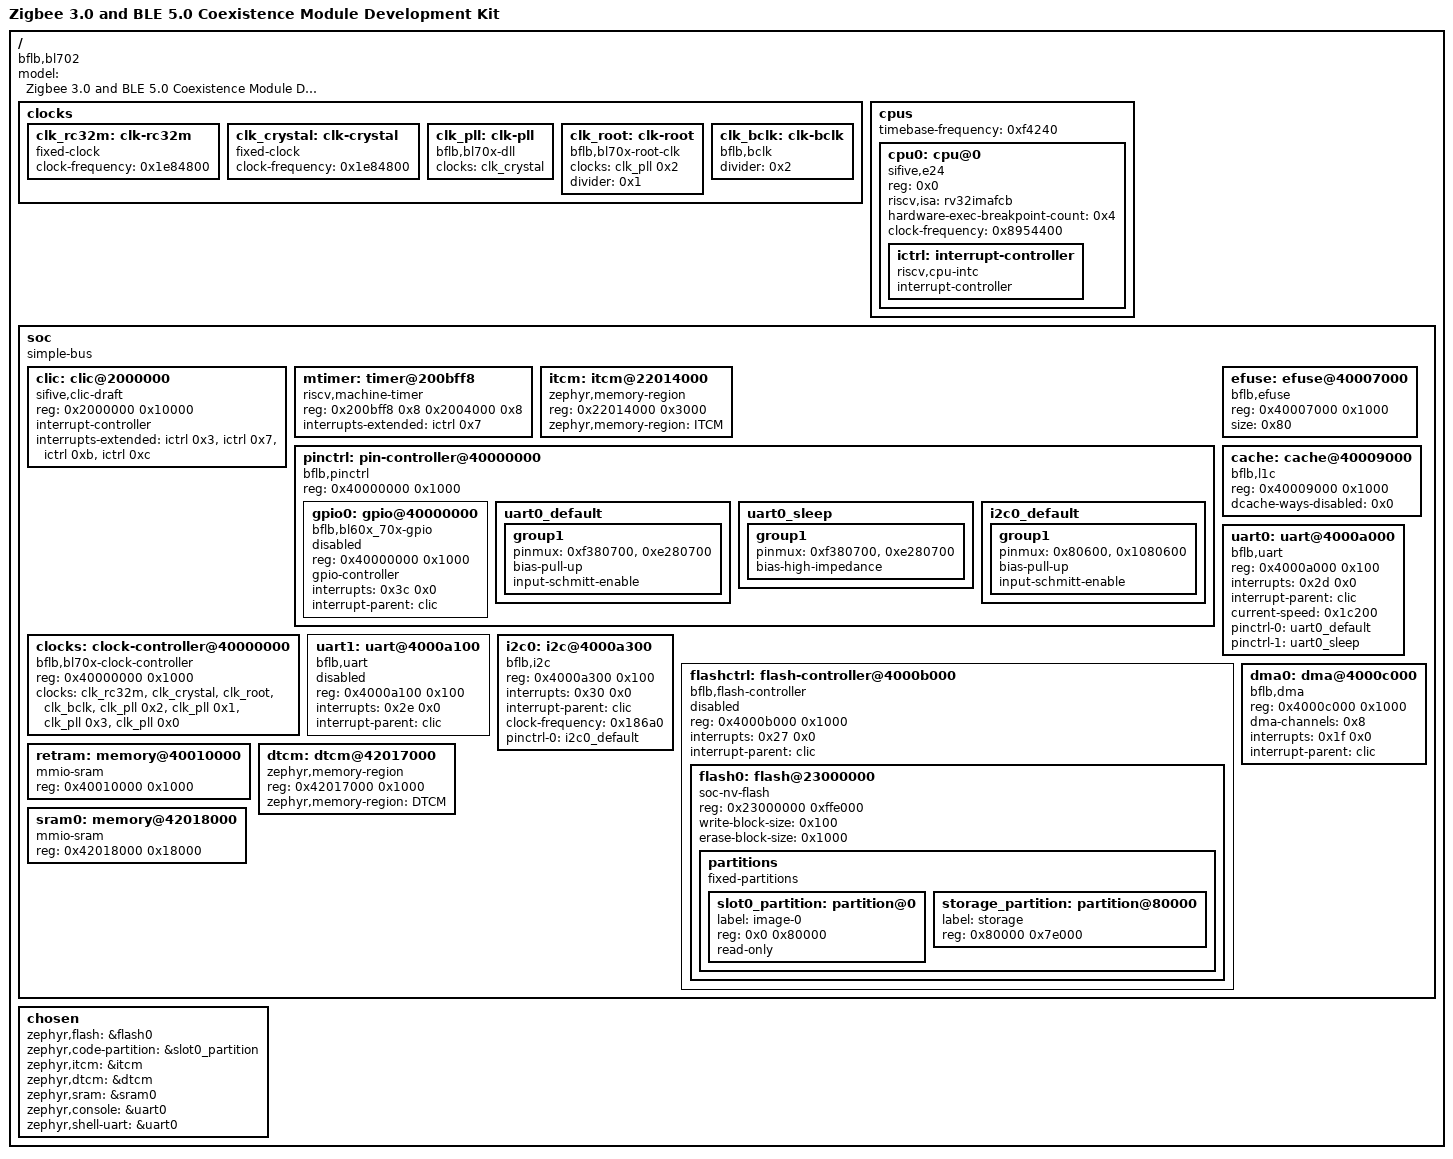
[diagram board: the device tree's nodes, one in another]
/dts-v1/;

/* node '/' defined in zephyr/dts/riscv/bflb/bl70x.dtsi:14 */
/ {
	#address-cells = < 0x1 >;                                            /* in zephyr/dts/riscv/bflb/bl70x.dtsi:15 */
	#size-cells = < 0x1 >;                                               /* in zephyr/dts/riscv/bflb/bl70x.dtsi:16 */
	model = "Zigbee 3.0 and BLE 5.0 Coexistence Module Development Kit"; /* in zephyr/boards/doiting/dt_xt_zb1_devkit/dt_xt_zb1_devkit.dts:12 */
	compatible = "bflb,bl702";                                           /* in zephyr/boards/doiting/dt_xt_zb1_devkit/dt_xt_zb1_devkit.dts:13 */

	/* node '/clocks' defined in zephyr/dts/riscv/bflb/bl70x.dtsi:18 */
	clocks {

		/* node '/clocks/clk-rc32m' defined in zephyr/dts/riscv/bflb/bl70x.dtsi:19 */
		clk_rc32m: clk-rc32m {
			#clock-cells = < 0x0 >;          /* in zephyr/dts/riscv/bflb/bl70x.dtsi:20 */
			compatible = "fixed-clock";      /* in zephyr/dts/riscv/bflb/bl70x.dtsi:21 */
			clock-frequency = < 0x1e84800 >; /* in zephyr/dts/riscv/bflb/bl70x.dtsi:22 */
			status = "okay";                 /* in zephyr/dts/riscv/bflb/bl70x.dtsi:23 */
			phandle = < 0x5 >;               /* in zephyr/dts/riscv/bflb/bl70x.dtsi:137 */
		};

		/* node '/clocks/clk-crystal' defined in zephyr/dts/riscv/bflb/bl70x.dtsi:26 */
		clk_crystal: clk-crystal {
			#clock-cells = < 0x0 >;          /* in zephyr/dts/riscv/bflb/bl70x.dtsi:27 */
			compatible = "fixed-clock";      /* in zephyr/dts/riscv/bflb/bl70x.dtsi:28 */
			clock-frequency = < 0x1e84800 >; /* in zephyr/dts/riscv/bflb/bl70x.dtsi:29 */
			status = "okay";                 /* in zephyr/dts/riscv/bflb/bl70x.dtsi:30 */
			phandle = < 0x1 >;               /* in zephyr/dts/riscv/bflb/bl70x.dtsi:36 */
		};

		/* node '/clocks/clk-pll' defined in zephyr/dts/riscv/bflb/bl70x.dtsi:33 */
		clk_pll: clk-pll {
			#clock-cells = < 0x1 >;        /* in zephyr/dts/riscv/bflb/bl70x.dtsi:34 */
			compatible = "bflb,bl70x-dll"; /* in zephyr/dts/riscv/bflb/bl70x.dtsi:35 */
			clocks = < &clk_crystal >;     /* in zephyr/dts/riscv/bflb/bl70x.dtsi:36 */
			status = "okay";               /* in zephyr/dts/riscv/bflb/bl70x.dtsi:37 */
			phandle = < 0x2 >;             /* in zephyr/dts/riscv/bflb/bl70x.dtsi:43 */
		};

		/* node '/clocks/clk-root' defined in zephyr/dts/riscv/bflb/bl70x.dtsi:40 */
		clk_root: clk-root {
			#clock-cells = < 0x0 >;             /* in zephyr/dts/riscv/bflb/bl70x.dtsi:41 */
			compatible = "bflb,bl70x-root-clk"; /* in zephyr/dts/riscv/bflb/bl70x.dtsi:42 */
			clocks = < &clk_pll 0x2 >;          /* in zephyr/dts/riscv/bflb/bl70x.dtsi:43 */
			divider = < 0x1 >;                  /* in zephyr/dts/riscv/bflb/bl70x.dtsi:44 */
			status = "okay";                    /* in zephyr/dts/riscv/bflb/bl70x.dtsi:45 */
			phandle = < 0x6 >;                  /* in zephyr/dts/riscv/bflb/bl70x.dtsi:137 */
		};

		/* node '/clocks/clk-bclk' defined in zephyr/dts/riscv/bflb/bl70x.dtsi:48 */
		clk_bclk: clk-bclk {
			#clock-cells = < 0x0 >;   /* in zephyr/dts/riscv/bflb/bl70x.dtsi:49 */
			compatible = "bflb,bclk"; /* in zephyr/dts/riscv/bflb/bl70x.dtsi:50 */
			divider = < 0x2 >;        /* in zephyr/dts/riscv/bflb/bl70x.dtsi:51 */
			status = "okay";          /* in zephyr/dts/riscv/bflb/bl70x.dtsi:52 */
			phandle = < 0x7 >;        /* in zephyr/dts/riscv/bflb/bl70x.dtsi:137 */
		};
	};

	/* node '/cpus' defined in zephyr/dts/riscv/bflb/bl70x.dtsi:56 */
	cpus {
		#address-cells = < 0x1 >;         /* in zephyr/dts/riscv/bflb/bl70x.dtsi:57 */
		#size-cells = < 0x0 >;            /* in zephyr/dts/riscv/bflb/bl70x.dtsi:58 */
		timebase-frequency = < 0xf4240 >; /* in zephyr/dts/riscv/bflb/bl70x.dtsi:59 */

		/* node '/cpus/cpu@0' defined in zephyr/dts/riscv/bflb/bl70x.dtsi:61 */
		cpu0: cpu@0 {
			device_type = "cpu";                      /* in zephyr/dts/riscv/bflb/bl70x.dtsi:62 */
			compatible = "sifive,e24",
			             "riscv";                     /* in zephyr/dts/riscv/bflb/bl70x.dtsi:63 */
			reg = < 0x0 >;                            /* in zephyr/dts/riscv/bflb/bl70x.dtsi:64 */
			riscv,isa = "rv32imafcb";                 /* in zephyr/dts/riscv/bflb/bl70x.dtsi:65 */
			hardware-exec-breakpoint-count = < 0x4 >; /* in zephyr/dts/riscv/bflb/bl70x.dtsi:66 */
			status = "okay";                          /* in zephyr/dts/riscv/bflb/bl70x.dtsi:67 */
			clock-frequency = < 0x8954400 >;          /* in zephyr/boards/doiting/dt_xt_zb1_devkit/dt_xt_zb1_devkit.dts:27 */

			/* node '/cpus/cpu@0/interrupt-controller' defined in zephyr/dts/riscv/bflb/bl70x.dtsi:69 */
			ictrl: interrupt-controller {
				#address-cells = < 0x0 >;      /* in zephyr/dts/riscv/bflb/bl70x.dtsi:70 */
				#interrupt-cells = < 0x1 >;    /* in zephyr/dts/riscv/bflb/bl70x.dtsi:71 */
				compatible = "riscv,cpu-intc"; /* in zephyr/dts/riscv/bflb/bl70x.dtsi:72 */
				interrupt-controller;          /* in zephyr/dts/riscv/bflb/bl70x.dtsi:73 */
				phandle = < 0x3 >;             /* in zephyr/dts/riscv/bflb/bl70x.dtsi:91 */
			};
		};
	};

	/* node '/soc' defined in zephyr/dts/riscv/bflb/bl70x.dtsi:78 */
	soc {
		compatible = "simple-bus"; /* in zephyr/dts/riscv/bflb/bl70x.dtsi:79 */
		#address-cells = < 0x1 >;  /* in zephyr/dts/riscv/bflb/bl70x.dtsi:80 */
		#size-cells = < 0x1 >;     /* in zephyr/dts/riscv/bflb/bl70x.dtsi:81 */
		ranges;                    /* in zephyr/dts/riscv/bflb/bl70x.dtsi:82 */

		/* node '/soc/clic@2000000' defined in zephyr/dts/riscv/bflb/bl70x.dtsi:84 */
		clic: clic@2000000 {
			compatible = "sifive,clic-draft";                                      /* in zephyr/dts/riscv/bflb/bl70x.dtsi:85 */
			reg = < 0x2000000 0x10000 >;                                           /* in zephyr/dts/riscv/bflb/bl70x.dtsi:86 */
			#address-cells = < 0x0 >;                                              /* in zephyr/dts/riscv/bflb/bl70x.dtsi:87 */
			#interrupt-cells = < 0x2 >;                                            /* in zephyr/dts/riscv/bflb/bl70x.dtsi:88 */
			interrupt-controller;                                                  /* in zephyr/dts/riscv/bflb/bl70x.dtsi:90 */
			interrupts-extended = < &ictrl 0x3 &ictrl 0x7 &ictrl 0xb &ictrl 0xc >; /* in zephyr/dts/riscv/bflb/bl70x.dtsi:91 */
			interrupt-names = "msip",
			                  "mtip",
			                  "meip",
			                  "csip";                                              /* in zephyr/dts/riscv/bflb/bl70x.dtsi:92 */
			phandle = < 0x4 >;                                                     /* in zephyr/dts/riscv/bflb/bl70x.dtsi:128 */
		};

		/* node '/soc/timer@200bff8' defined in zephyr/dts/riscv/bflb/bl70x.dtsi:98 */
		mtimer: timer@200bff8 {
			compatible = "riscv,machine-timer";    /* in zephyr/dts/riscv/bflb/bl70x.dtsi:99 */
			reg = < 0x200bff8 0x8 0x2004000 0x8 >; /* in zephyr/dts/riscv/bflb/bl70x.dtsi:100 */
			reg-names = "mtime",
			            "mtimecmp";                /* in zephyr/dts/riscv/bflb/bl70x.dtsi:101 */
			interrupts-extended = < &ictrl 0x7 >;  /* in zephyr/dts/riscv/bflb/bl70x.dtsi:103 */
		};

		/* node '/soc/itcm@22014000' defined in zephyr/dts/riscv/bflb/bl70x.dtsi:106 */
		itcm: itcm@22014000 {
			compatible = "zephyr,memory-region",
			             "sifive,dtim0";         /* in zephyr/dts/riscv/bflb/bl70x.dtsi:107 */
			reg = < 0x22014000 0x3000 >;         /* in zephyr/dts/riscv/bflb/bl70x.dtsi:108 */
			zephyr,memory-region = "ITCM";       /* in zephyr/dts/riscv/bflb/bl70x.dtsi:109 */
		};

		/* node '/soc/pin-controller@40000000' defined in zephyr/dts/riscv/bflb/bl70x.dtsi:112 */
		pinctrl: pin-controller@40000000 {
			compatible = "bflb,pinctrl";               /* in zephyr/dts/riscv/bflb/bl70x.dtsi:113 */
			reg = < 0x40000000 0x1000 >;               /* in zephyr/dts/riscv/bflb/bl70x.dtsi:114 */
			ranges = < 0x40000000 0x40000000 0x1000 >; /* in zephyr/dts/riscv/bflb/bl70x.dtsi:115 */
			#address-cells = < 0x1 >;                  /* in zephyr/dts/riscv/bflb/bl70x.dtsi:116 */
			#size-cells = < 0x1 >;                     /* in zephyr/dts/riscv/bflb/bl70x.dtsi:117 */
			status = "okay";                           /* in zephyr/dts/riscv/bflb/bl70x.dtsi:118 */

			/* node '/soc/pin-controller@40000000/gpio@40000000' defined in zephyr/dts/riscv/bflb/bl70x.dtsi:120 */
			gpio0: gpio@40000000 {
				compatible = "bflb,bl60x_70x-gpio"; /* in zephyr/dts/riscv/bflb/bl70x.dtsi:121 */
				reg = < 0x40000000 0x1000 >;        /* in zephyr/dts/riscv/bflb/bl70x.dtsi:122 */
				#gpio-cells = < 0x2 >;              /* in zephyr/dts/riscv/bflb/bl70x.dtsi:123 */
				status = "disabled";                /* in zephyr/dts/riscv/bflb/bl70x.dtsi:124 */
				gpio-controller;                    /* in zephyr/dts/riscv/bflb/bl70x.dtsi:126 */
				interrupts = < 0x3c 0x0 >;          /* in zephyr/dts/riscv/bflb/bl70x.dtsi:127 */
				interrupt-parent = < &clic >;       /* in zephyr/dts/riscv/bflb/bl70x.dtsi:128 */
			};

			/* node '/soc/pin-controller@40000000/uart0_default' defined in zephyr/boards/doiting/dt_xt_zb1_devkit/dt_xt_zb1_devkit-pinctrl.dtsi:9 */
			uart0_default: uart0_default {
				phandle = < 0x8 >; /* in zephyr/boards/doiting/dt_xt_zb1_devkit/dt_xt_zb1_devkit.dts:60 */

				/* node '/soc/pin-controller@40000000/uart0_default/group1' defined in zephyr/boards/doiting/dt_xt_zb1_devkit/dt_xt_zb1_devkit-pinctrl.dtsi:10 */
				group1 {
					pinmux = < 0xf380700 >,
					         < 0xe280700 >; /* in zephyr/boards/doiting/dt_xt_zb1_devkit/dt_xt_zb1_devkit-pinctrl.dtsi:11 */
					bias-pull-up;           /* in zephyr/boards/doiting/dt_xt_zb1_devkit/dt_xt_zb1_devkit-pinctrl.dtsi:13 */
					input-schmitt-enable;   /* in zephyr/boards/doiting/dt_xt_zb1_devkit/dt_xt_zb1_devkit-pinctrl.dtsi:14 */
				};
			};

			/* node '/soc/pin-controller@40000000/uart0_sleep' defined in zephyr/boards/doiting/dt_xt_zb1_devkit/dt_xt_zb1_devkit-pinctrl.dtsi:18 */
			uart0_sleep: uart0_sleep {
				phandle = < 0x9 >; /* in zephyr/boards/doiting/dt_xt_zb1_devkit/dt_xt_zb1_devkit.dts:61 */

				/* node '/soc/pin-controller@40000000/uart0_sleep/group1' defined in zephyr/boards/doiting/dt_xt_zb1_devkit/dt_xt_zb1_devkit-pinctrl.dtsi:19 */
				group1 {
					pinmux = < 0xf380700 >,
					         < 0xe280700 >; /* in zephyr/boards/doiting/dt_xt_zb1_devkit/dt_xt_zb1_devkit-pinctrl.dtsi:20 */
					bias-high-impedance;    /* in zephyr/boards/doiting/dt_xt_zb1_devkit/dt_xt_zb1_devkit-pinctrl.dtsi:22 */
				};
			};

			/* node '/soc/pin-controller@40000000/i2c0_default' defined in zephyr/boards/doiting/dt_xt_zb1_devkit/dt_xt_zb1_devkit-pinctrl.dtsi:26 */
			i2c0_default: i2c0_default {
				phandle = < 0xa >; /* in zephyr/boards/doiting/dt_xt_zb1_devkit/dt_xt_zb1_devkit.dts:69 */

				/* node '/soc/pin-controller@40000000/i2c0_default/group1' defined in zephyr/boards/doiting/dt_xt_zb1_devkit/dt_xt_zb1_devkit-pinctrl.dtsi:27 */
				group1 {
					pinmux = < 0x80600 >,
					         < 0x1080600 >; /* in zephyr/boards/doiting/dt_xt_zb1_devkit/dt_xt_zb1_devkit-pinctrl.dtsi:28 */
					bias-pull-up;           /* in zephyr/boards/doiting/dt_xt_zb1_devkit/dt_xt_zb1_devkit-pinctrl.dtsi:30 */
					input-schmitt-enable;   /* in zephyr/boards/doiting/dt_xt_zb1_devkit/dt_xt_zb1_devkit-pinctrl.dtsi:31 */
				};
			};
		};

		/* node '/soc/clock-controller@40000000' defined in zephyr/dts/riscv/bflb/bl70x.dtsi:132 */
		clocks: clock-controller@40000000 {
			compatible = "bflb,bl70x-clock-controller",
			             "bflb,clock-controller";       /* in zephyr/dts/riscv/bflb/bl70x.dtsi:133 */
			reg = < 0x40000000 0x1000 >;                /* in zephyr/dts/riscv/bflb/bl70x.dtsi:134 */
			#clock-cells = < 0x1 >;                     /* in zephyr/dts/riscv/bflb/bl70x.dtsi:135 */
			status = "okay";                            /* in zephyr/dts/riscv/bflb/bl70x.dtsi:136 */
			clocks = < &clk_rc32m >,
			         < &clk_crystal >,
			         < &clk_root >,
			         < &clk_bclk >,
			         < &clk_pll 0x2 >,
			         < &clk_pll 0x1 >,
			         < &clk_pll 0x3 >,
			         < &clk_pll 0x0 >;                  /* in zephyr/dts/riscv/bflb/bl70x.dtsi:137 */
			clock-names = "rc32m",
			              "crystal",
			              "root",
			              "bclk",
			              "dll_144",
			              "dll_96",
			              "dll_120",
			              "dll_57";                     /* in zephyr/dts/riscv/bflb/bl70x.dtsi:140 */
		};

		/* node '/soc/efuse@40007000' defined in zephyr/dts/riscv/bflb/bl70x.dtsi:145 */
		efuse: efuse@40007000 {
			compatible = "bflb,efuse";   /* in zephyr/dts/riscv/bflb/bl70x.dtsi:146 */
			reg = < 0x40007000 0x1000 >; /* in zephyr/dts/riscv/bflb/bl70x.dtsi:147 */
			status = "okay";             /* in zephyr/dts/riscv/bflb/bl70x.dtsi:148 */
			size = < 0x80 >;             /* in zephyr/dts/riscv/bflb/bl70x.dtsi:149 */
		};

		/* node '/soc/cache@40009000' defined in zephyr/dts/riscv/bflb/bl70x.dtsi:152 */
		cache: cache@40009000 {
			reg = < 0x40009000 0x1000 >;    /* in zephyr/dts/riscv/bflb/bl70x.dtsi:153 */
			compatible = "bflb,l1c";        /* in zephyr/dts/riscv/bflb/bl70x.dtsi:154 */
			dcache-ways-disabled = < 0x0 >; /* in zephyr/dts/riscv/bflb/bl70x.dtsi:155 */
		};

		/* node '/soc/uart@4000a000' defined in zephyr/dts/riscv/bflb/bl70x.dtsi:158 */
		uart0: uart@4000a000 {
			compatible = "bflb,uart";       /* in zephyr/dts/riscv/bflb/bl70x.dtsi:159 */
			reg = < 0x4000a000 0x100 >;     /* in zephyr/dts/riscv/bflb/bl70x.dtsi:160 */
			interrupts = < 0x2d 0x0 >;      /* in zephyr/dts/riscv/bflb/bl70x.dtsi:161 */
			interrupt-parent = < &clic >;   /* in zephyr/dts/riscv/bflb/bl70x.dtsi:162 */
			status = "okay";                /* in zephyr/boards/doiting/dt_xt_zb1_devkit/dt_xt_zb1_devkit.dts:57 */
			current-speed = < 0x1c200 >;    /* in zephyr/boards/doiting/dt_xt_zb1_devkit/dt_xt_zb1_devkit.dts:58 */
			pinctrl-0 = < &uart0_default >; /* in zephyr/boards/doiting/dt_xt_zb1_devkit/dt_xt_zb1_devkit.dts:60 */
			pinctrl-1 = < &uart0_sleep >;   /* in zephyr/boards/doiting/dt_xt_zb1_devkit/dt_xt_zb1_devkit.dts:61 */
			pinctrl-names = "default",
			                "sleep";        /* in zephyr/boards/doiting/dt_xt_zb1_devkit/dt_xt_zb1_devkit.dts:62 */
		};

		/* node '/soc/uart@4000a100' defined in zephyr/dts/riscv/bflb/bl70x.dtsi:166 */
		uart1: uart@4000a100 {
			compatible = "bflb,uart";     /* in zephyr/dts/riscv/bflb/bl70x.dtsi:167 */
			reg = < 0x4000a100 0x100 >;   /* in zephyr/dts/riscv/bflb/bl70x.dtsi:168 */
			interrupts = < 0x2e 0x0 >;    /* in zephyr/dts/riscv/bflb/bl70x.dtsi:169 */
			interrupt-parent = < &clic >; /* in zephyr/dts/riscv/bflb/bl70x.dtsi:170 */
			status = "disabled";          /* in zephyr/dts/riscv/bflb/bl70x.dtsi:171 */
		};

		/* node '/soc/i2c@4000a300' defined in zephyr/dts/riscv/bflb/bl70x.dtsi:174 */
		i2c0: i2c@4000a300 {
			compatible = "bflb,i2c";       /* in zephyr/dts/riscv/bflb/bl70x.dtsi:175 */
			reg = < 0x4000a300 0x100 >;    /* in zephyr/dts/riscv/bflb/bl70x.dtsi:176 */
			#address-cells = < 0x1 >;      /* in zephyr/dts/riscv/bflb/bl70x.dtsi:177 */
			#size-cells = < 0x0 >;         /* in zephyr/dts/riscv/bflb/bl70x.dtsi:178 */
			interrupts = < 0x30 0x0 >;     /* in zephyr/dts/riscv/bflb/bl70x.dtsi:181 */
			interrupt-parent = < &clic >;  /* in zephyr/dts/riscv/bflb/bl70x.dtsi:182 */
			status = "okay";               /* in zephyr/boards/doiting/dt_xt_zb1_devkit/dt_xt_zb1_devkit.dts:66 */
			clock-frequency = < 0x186a0 >; /* in zephyr/boards/doiting/dt_xt_zb1_devkit/dt_xt_zb1_devkit.dts:67 */
			pinctrl-0 = < &i2c0_default >; /* in zephyr/boards/doiting/dt_xt_zb1_devkit/dt_xt_zb1_devkit.dts:69 */
			pinctrl-names = "default";     /* in zephyr/boards/doiting/dt_xt_zb1_devkit/dt_xt_zb1_devkit.dts:70 */
		};

		/* node '/soc/flash-controller@4000b000' defined in zephyr/dts/riscv/bflb/bl70x.dtsi:185 */
		flashctrl: flash-controller@4000b000 {
			compatible = "bflb,flash-controller"; /* in zephyr/dts/riscv/bflb/bl70x.dtsi:186 */
			reg = < 0x4000b000 0x1000 >;          /* in zephyr/dts/riscv/bflb/bl70x.dtsi:187 */
			#address-cells = < 0x1 >;             /* in zephyr/dts/riscv/bflb/bl70x.dtsi:188 */
			#size-cells = < 0x1 >;                /* in zephyr/dts/riscv/bflb/bl70x.dtsi:189 */
			status = "disabled";                  /* in zephyr/dts/riscv/bflb/bl70x.dtsi:190 */
			interrupts = < 0x27 0x0 >;            /* in zephyr/dts/riscv/bflb/bl70x.dtsi:192 */
			interrupt-parent = < &clic >;         /* in zephyr/dts/riscv/bflb/bl70x.dtsi:193 */

			/* node '/soc/flash-controller@4000b000/flash@23000000' defined in zephyr/boards/doiting/dt_xt_zb1_devkit/dt_xt_zb1_devkit.dts:31 */
			flash0: flash@23000000 {
				compatible = "soc-nv-flash",
				             "mxicy,kh25v80";  /* in zephyr/boards/doiting/dt_xt_zb1_devkit/dt_xt_zb1_devkit.dts:32 */
				reg = < 0x23000000 0xffe000 >; /* in zephyr/boards/doiting/dt_xt_zb1_devkit/dt_xt_zb1_devkit.dts:33 */
				write-block-size = < 0x100 >;  /* in zephyr/boards/doiting/dt_xt_zb1_devkit/dt_xt_zb1_devkit.dts:34 */
				erase-block-size = < 0x1000 >; /* in zephyr/boards/doiting/dt_xt_zb1_devkit/dt_xt_zb1_devkit.dts:35 */

				/* node '/soc/flash-controller@4000b000/flash@23000000/partitions' defined in zephyr/boards/doiting/dt_xt_zb1_devkit/dt_xt_zb1_devkit.dts:37 */
				partitions {
					compatible = "fixed-partitions"; /* in zephyr/boards/doiting/dt_xt_zb1_devkit/dt_xt_zb1_devkit.dts:38 */
					#address-cells = < 0x1 >;        /* in zephyr/boards/doiting/dt_xt_zb1_devkit/dt_xt_zb1_devkit.dts:39 */
					#size-cells = < 0x1 >;           /* in zephyr/boards/doiting/dt_xt_zb1_devkit/dt_xt_zb1_devkit.dts:40 */

					/* node '/soc/flash-controller@4000b000/flash@23000000/partitions/partition@0' defined in zephyr/boards/doiting/dt_xt_zb1_devkit/dt_xt_zb1_devkit.dts:42 */
					slot0_partition: partition@0 {
						label = "image-0";     /* in zephyr/boards/doiting/dt_xt_zb1_devkit/dt_xt_zb1_devkit.dts:43 */
						reg = < 0x0 0x80000 >; /* in zephyr/boards/doiting/dt_xt_zb1_devkit/dt_xt_zb1_devkit.dts:44 */
						read-only;             /* in zephyr/boards/doiting/dt_xt_zb1_devkit/dt_xt_zb1_devkit.dts:45 */
					};

					/* node '/soc/flash-controller@4000b000/flash@23000000/partitions/partition@80000' defined in zephyr/boards/doiting/dt_xt_zb1_devkit/dt_xt_zb1_devkit.dts:48 */
					storage_partition: partition@80000 {
						label = "storage";         /* in zephyr/boards/doiting/dt_xt_zb1_devkit/dt_xt_zb1_devkit.dts:49 */
						reg = < 0x80000 0x7e000 >; /* in zephyr/boards/doiting/dt_xt_zb1_devkit/dt_xt_zb1_devkit.dts:50 */
					};
				};
			};
		};

		/* node '/soc/dma@4000c000' defined in zephyr/dts/riscv/bflb/bl70x.dtsi:196 */
		dma0: dma@4000c000 {
			compatible = "bflb,dma";      /* in zephyr/dts/riscv/bflb/bl70x.dtsi:197 */
			reg = < 0x4000c000 0x1000 >;  /* in zephyr/dts/riscv/bflb/bl70x.dtsi:198 */
			#dma-cells = < 0x1 >;         /* in zephyr/dts/riscv/bflb/bl70x.dtsi:199 */
			dma-channels = < 0x8 >;       /* in zephyr/dts/riscv/bflb/bl70x.dtsi:200 */
			interrupts = < 0x1f 0x0 >;    /* in zephyr/dts/riscv/bflb/bl70x.dtsi:202 */
			interrupt-parent = < &clic >; /* in zephyr/dts/riscv/bflb/bl70x.dtsi:203 */
		};

		/* node '/soc/memory@40010000' defined in zephyr/dts/riscv/bflb/bl70x.dtsi:206 */
		retram: memory@40010000 {
			compatible = "mmio-sram";    /* in zephyr/dts/riscv/bflb/bl70x.dtsi:207 */
			reg = < 0x40010000 0x1000 >; /* in zephyr/dts/riscv/bflb/bl70x.dtsi:208 */
		};

		/* node '/soc/dtcm@42017000' defined in zephyr/dts/riscv/bflb/bl70x.dtsi:211 */
		dtcm: dtcm@42017000 {
			compatible = "zephyr,memory-region",
			             "sifive,dtim0";         /* in zephyr/dts/riscv/bflb/bl70x.dtsi:212 */
			reg = < 0x42017000 0x1000 >;         /* in zephyr/dts/riscv/bflb/bl70x.dtsi:213 */
			zephyr,memory-region = "DTCM";       /* in zephyr/dts/riscv/bflb/bl70x.dtsi:214 */
		};

		/* node '/soc/memory@42018000' defined in zephyr/dts/riscv/bflb/bl70x.dtsi:217 */
		sram0: memory@42018000 {
			compatible = "mmio-sram";     /* in zephyr/dts/riscv/bflb/bl70x.dtsi:218 */
			reg = < 0x42018000 0x18000 >; /* in zephyr/dts/riscv/bflb/bl70x.dtsi:219 */
		};
	};

	/* node '/chosen' defined in zephyr/boards/doiting/dt_xt_zb1_devkit/dt_xt_zb1_devkit.dts:15 */
	chosen {
		zephyr,flash = &flash0;                   /* in zephyr/boards/doiting/dt_xt_zb1_devkit/dt_xt_zb1_devkit.dts:16 */
		zephyr,code-partition = &slot0_partition; /* in zephyr/boards/doiting/dt_xt_zb1_devkit/dt_xt_zb1_devkit.dts:17 */
		zephyr,itcm = &itcm;                      /* in zephyr/boards/doiting/dt_xt_zb1_devkit/dt_xt_zb1_devkit.dts:18 */
		zephyr,dtcm = &dtcm;                      /* in zephyr/boards/doiting/dt_xt_zb1_devkit/dt_xt_zb1_devkit.dts:19 */
		zephyr,sram = &sram0;                     /* in zephyr/boards/doiting/dt_xt_zb1_devkit/dt_xt_zb1_devkit.dts:20 */
		zephyr,console = &uart0;                  /* in zephyr/boards/doiting/dt_xt_zb1_devkit/dt_xt_zb1_devkit.dts:21 */
		zephyr,shell-uart = &uart0;               /* in zephyr/boards/doiting/dt_xt_zb1_devkit/dt_xt_zb1_devkit.dts:22 */
	};
};
